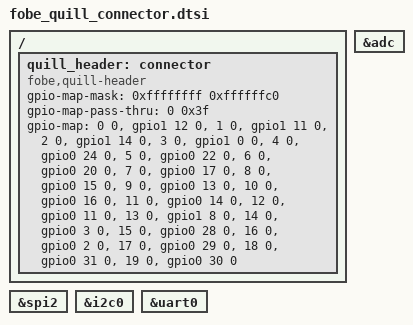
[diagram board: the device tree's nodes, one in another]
/*
 * Copyright (c) 2025 Chiho Sin
 *
 * SPDX-License-Identifier: Apache-2.0
 */

/ {
	quill_header: connector {
		compatible = "fobe,quill-header";
		#gpio-cells = <2>;
		gpio-map-mask = <0xffffffff 0xffffffc0>;
		gpio-map-pass-thru = <0 0x3f>;
		gpio-map = <0 0 &gpio1 12 0>,	/* D0 */
			   <1 0 &gpio1 11 0>,	/* D1 */
			   <2 0 &gpio1 14 0>,	/* D2 */
			   <3 0 &gpio1 0 0>,	/* D3 */
			   <4 0 &gpio0 24 0>,	/* D4 */
			   <5 0 &gpio0 22 0>,	/* D5 */
			   <6 0 &gpio0 20 0>,	/* D6 */
			   <7 0 &gpio0 17 0>,	/* D7 */
			   <8 0 &gpio0 15 0>,	/* D8 */
			   <9 0 &gpio0 13 0>,	/* D9 */
			   <10 0 &gpio0 16 0>,	/* D10 */
			   <11 0 &gpio0 14 0>,	/* D11 */
			   <12 0 &gpio0 11 0>,	/* D12 */
			   <13 0 &gpio1 8 0>,	/* D13 */
			   <14 0 &gpio0 3 0>,	/* A0 */
			   <15 0 &gpio0 28 0>,	/* A1 */
			   <16 0 &gpio0 2 0>,	/* A2 */
			   <17 0 &gpio0 29 0>,	/* A3 */
			   <18 0 &gpio0 31 0>,	/* A4 */
			   <19 0 &gpio0 30 0>;	/* A5 */
	};
};

quill_spi: &spi2 {};

quill_i2c: &i2c0 {};

quill_serial: &uart0 {};

quill_adc: &adc {};
